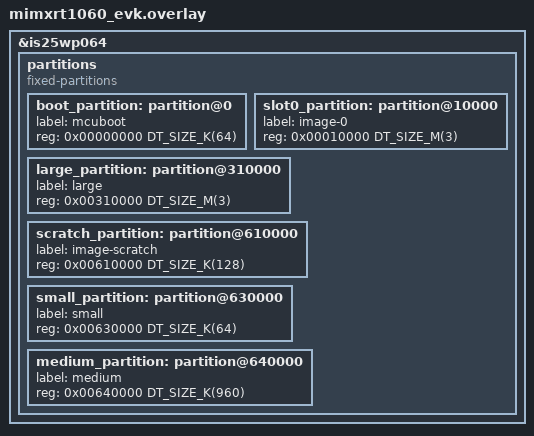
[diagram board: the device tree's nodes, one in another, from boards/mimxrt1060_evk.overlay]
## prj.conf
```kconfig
CONFIG_FILE_SYSTEM=y
CONFIG_FILE_SYSTEM_MKFS=y
CONFIG_FILE_SYSTEM_LITTLEFS=y
CONFIG_ZTEST_NEW_API=y
CONFIG_MAIN_STACK_SIZE=4096

# Performance tests need custom buffer allocation
CONFIG_COMMON_LIBC_MALLOC_ARENA_SIZE=8192

# FS abstraction layer is noisy so it's off.  Turn it on to see the
# littlefs configuration parameters.
#CONFIG_LOG=y
#CONFIG_FS_LOG_LEVEL_DBG=y

CONFIG_FLASH=y
CONFIG_FLASH_MAP=y
CONFIG_FLASH_PAGE_LAYOUT=y

CONFIG_ZTEST=y
CONFIG_ZTEST_STACK_SIZE=4096
```

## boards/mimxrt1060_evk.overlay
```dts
/*
 * Copyright (c) 2021 NXP
 *
 * SPDX-License-Identifier: Apache-2.0
 */

&is25wp064 {
	partitions {
		compatible = "fixed-partitions";
		#address-cells = <1>;
		#size-cells = <1>;

		boot_partition: partition@0 {
			label = "mcuboot";
			reg = <0x00000000 DT_SIZE_K(64)>;
		};
		slot0_partition: partition@10000 {
			label = "image-0";
			reg = <0x00010000 DT_SIZE_M(3)>;
		};
		large_partition: partition@310000 {
			label = "large";
			reg = <0x00310000 DT_SIZE_M(3)>;
		};
		scratch_partition: partition@610000 {
			label = "image-scratch";
			reg = <0x00610000 DT_SIZE_K(128)>;
		};
		small_partition: partition@630000 {
			label = "small";
			reg = <0x00630000 DT_SIZE_K(64)>;
		};
		medium_partition: partition@640000 {
			label = "medium";
			reg = <0x00640000 DT_SIZE_K(960)>;
		};
	};
};
```

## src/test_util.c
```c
/*
 * Copyright (c) 2019 Peter Bigot Consulting, LLC
 *
 * SPDX-License-Identifier: Apache-2.0
 */

/* Tests of functions in testfs_util */

#include <string.h>
#include <zephyr/ztest.h>
#include "testfs_tests.h"
#include "../../common/test_fs_util.h"

#define MNT "/mnt"
#define ELT1 "a"
#define ELT2 "b"

static struct testfs_path path;
static const struct fs_mount_t mnt = {
	.mnt_point = MNT,
};

static inline struct testfs_path *reset_path()
{
	testfs_path_init(&path, &mnt, TESTFS_PATH_END);
	return &path;
}

ZTEST(littlefs, test_util_path_init_base)
{
	zassert_equal(testfs_path_init(&path, NULL, TESTFS_PATH_END),
		      path.path,
		      "bad root init return");
	zassert_equal(strcmp(path.path, "/"), 0, "bad root init path");

	zassert_equal(testfs_path_init(&path, &mnt, TESTFS_PATH_END),
		      path.path,
		      "bad mnt init return");
	zassert_equal(strcmp(path.path, mnt.mnt_point), 0, "bad mnt init path");

	if (IS_ENABLED(CONFIG_DEBUG)) {
		struct fs_mount_t invalid = {
			.mnt_point = "relative",
		};

		/* Apparently no way to verify this without panic. */
		testfs_path_init(&path, &invalid, TESTFS_PATH_END);
	}
}

ZTEST(littlefs, test_util_path_init_overrun)
{
	char overrun[TESTFS_PATH_MAX + 2] = "/";
	size_t overrun_max = sizeof(overrun) - 1;
	size_t path_max = sizeof(path.path) - 1;
	struct fs_mount_t overrun_mnt = {
		.mnt_point = overrun,
	};

	zassert_true(path_max < overrun_max,
		     "path length requirements unmet");

	memset(overrun + 1, 'A', overrun_max - 1);

	zassert_equal(testfs_path_init(&path, &overrun_mnt, TESTFS_PATH_END),
		      path.path,
		      "bad overrun init return");
	zassert_true(strcmp(path.path, overrun) < 0,
		     "bad overrun init");
	zassert_equal(strncmp(path.path, overrun, path_max),
		      0,
		      "bad overrun path");
	zassert_equal(path.path[path_max], '\0',
		      "missing overrun EOS");
}

ZTEST(littlefs, test_util_path_init_extended)
{
	zassert_equal(strcmp(testfs_path_init(&path, &mnt,
					      ELT1,
					      TESTFS_PATH_END),
			     MNT "/" ELT1),
		      0,
		      "bad mnt init elt1");

	zassert_equal(strcmp(testfs_path_init(&path, &mnt,
					      ELT1,
					      ELT2,
					      TESTFS_PATH_END),
			     MNT "/" ELT1 "/" ELT2),
		      0,
		      "bad mnt init elt1 elt2");
}

ZTEST(littlefs, test_util_path_extend)
{
	zassert_equal(strcmp(testfs_path_extend(reset_path(),
						TESTFS_PATH_END),
			     MNT),
		      0,
		      "empty extend failed");

	zassert_equal(strcmp(testfs_path_extend(reset_path(),
						ELT2,
						TESTFS_PATH_END),
			     MNT "/" ELT2),
		      0,
		      "elt extend failed");

	zassert_equal(strcmp(testfs_path_extend(reset_path(),
						ELT1,
						ELT2,
						TESTFS_PATH_END),
			     MNT "/" ELT1 "/" ELT2),
		      0,
		      "elt1 elt2 extend failed");
}

ZTEST(littlefs, test_util_path_extend_up)
{
	zassert_equal(strcmp(testfs_path_extend(reset_path(),
						ELT2,
						"..",
						ELT1,
						TESTFS_PATH_END),
			     MNT "/" ELT1),
		      0,
		      "elt elt2, up, elt1 failed");

	zassert_equal(strcmp(testfs_path_extend(reset_path(),
						"..",
						TESTFS_PATH_END),
			     "/"),
		      0,
		      "up strip mnt failed");

	zassert_equal(strcmp(testfs_path_extend(reset_path(),
						"..",
						"..",
						TESTFS_PATH_END),
			     "/"),
		      0,
		      "up from root failed");
}

ZTEST(littlefs, test_util_path_extend_overrun)
{
	char long_elt[TESTFS_PATH_MAX];

	memset(long_elt, 'a', sizeof(long_elt) - 1);
	long_elt[sizeof(long_elt) - 1] = '\0';

	zassert_equal(strcmp(testfs_path_extend(reset_path(),
						long_elt,
						ELT1,
						TESTFS_PATH_END),
			     MNT),
		      0,
		      "stop at overrun failed");
}
```

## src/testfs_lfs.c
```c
/*
 * Copyright (c) 2019 Peter Bigot Consulting, LLC
 *
 * SPDX-License-Identifier: Apache-2.0
 */

#include <zephyr/ztest.h>
#include <zephyr/fs/littlefs.h>
#include <zephyr/storage/flash_map.h>
#include "testfs_lfs.h"

#define SMALL_PARTITION		small_partition
#define SMALL_PARTITION_ID	FIXED_PARTITION_ID(SMALL_PARTITION)

#define MEDIUM_PARTITION	medium_partition
#define MEDIUM_PARTITION_ID	FIXED_PARTITION_ID(MEDIUM_PARTITION)

#define LARGE_PARTITION		large_partition
#define LARGE_PARTITION_ID	FIXED_PARTITION_ID(LARGE_PARTITION)

FS_LITTLEFS_DECLARE_DEFAULT_CONFIG(small);
struct fs_mount_t testfs_small_mnt = {
	.type = FS_LITTLEFS,
	.fs_data = &small,
	.storage_dev = (void *)SMALL_PARTITION_ID,
	.mnt_point = TESTFS_MNT_POINT_SMALL,
};

#if CONFIG_APP_TEST_CUSTOM
FS_LITTLEFS_DECLARE_CUSTOM_CONFIG(medium, 4, MEDIUM_IO_SIZE, MEDIUM_IO_SIZE,
				  MEDIUM_CACHE_SIZE, MEDIUM_LOOKAHEAD_SIZE);
struct fs_mount_t testfs_medium_mnt = {
	.type = FS_LITTLEFS,
	.fs_data = &medium,
	.storage_dev = (void *)MEDIUM_PARTITION_ID,
	.mnt_point = TESTFS_MNT_POINT_MEDIUM,
};

static uint8_t large_read_buffer[LARGE_CACHE_SIZE];
static uint8_t large_prog_buffer[LARGE_CACHE_SIZE];
static uint32_t large_lookahead_buffer[LARGE_LOOKAHEAD_SIZE / 4U];
static struct fs_littlefs large = {
	.cfg = {
		.read_size = LARGE_IO_SIZE,
		.prog_size = LARGE_IO_SIZE,
		.cache_size = LARGE_CACHE_SIZE,
		.lookahead_size = LARGE_LOOKAHEAD_SIZE,
		.block_size = 32768, /* increase erase size */
		.read_buffer = large_read_buffer,
		.prog_buffer = large_prog_buffer,
		.lookahead_buffer = large_lookahead_buffer,
	},
};
struct fs_mount_t testfs_large_mnt = {
	.type = FS_LITTLEFS,
	.fs_data = &large,
	.storage_dev = (void *)LARGE_PARTITION_ID,
	.mnt_point = TESTFS_MNT_POINT_LARGE,
};

#endif /* CONFIG_APP_TEST_CUSTOM */

int testfs_lfs_wipe_partition(const struct fs_mount_t *mp)
{
	unsigned int id = (uintptr_t)mp->storage_dev;
	const struct flash_area *pfa;
	int rc = flash_area_open(id, &pfa);

	if (rc < 0) {
		TC_PRINT("Error accessing flash area %u [%d]\n",
			 id, rc);
		return TC_FAIL;
	}

	TC_PRINT("Erasing %zu (0x%zx) bytes\n", pfa->fa_size, pfa->fa_size);
	rc = flash_area_erase(pfa, 0, pfa->fa_size);
	(void)flash_area_close(pfa);

	if (rc < 0) {
		TC_PRINT("Error wiping flash area %u [%d]\n",
			 id, rc);
		return TC_FAIL;
	}

	TC_PRINT("Wiped flash area %u for %s\n", id, mp->mnt_point);
	return TC_PASS;
}
```
